# M55M1 register map
File version: 1.0
Registers are 32-bit, read-write, reset 0x0 unless marked. A register's access mark holds for its fields unless they carry their own. Offsets are from the block's base; [hi:lo] are bit positions; {n}, {i} and the like mark numbered series; 'fields as' and 'values as' point back to an identical list.

## SCU — SCU Register Map
Base 0x40402000
0x00 SCU_D0PNS0 — Domain 0 Peripheral Non-secure Attribution Set Register0 (0x4000_0000~0x4001_FFFF)
  [3] NPU — Set NPU to Non-secure State
    0=NPU is a secure module (default); 1=NPU is a non-secure module
0x08 SCU_D0PNS2 — Domain 0 Peripheral Non-secure Attribution Set Register2 (0x4004_0000~0x4005_FFFF)
  [2] SPIM0 — Set SPIM0 to Non-secure State
    0=SPIM0 is a secure module (default); 1=SPIM0 is a non-secure module
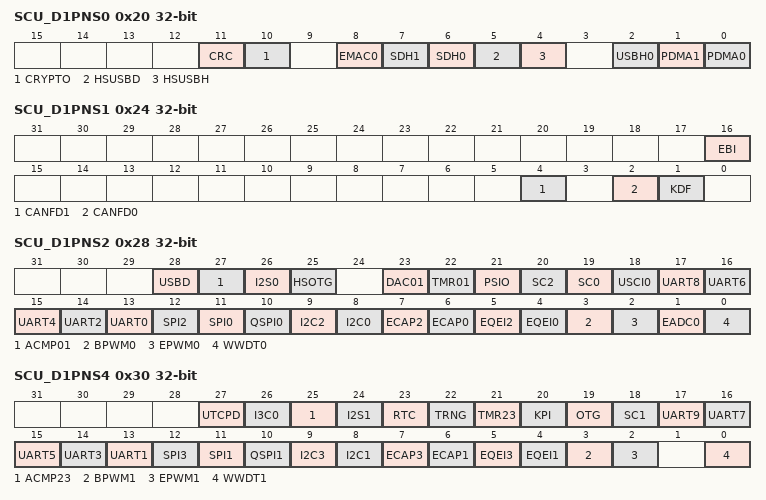
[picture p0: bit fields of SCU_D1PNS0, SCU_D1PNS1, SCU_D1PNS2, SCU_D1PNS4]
0x20 SCU_D1PNS0 — Domain 1 Peripheral Non-secure Attribution Set Register0 (0x4020_0000~0x4021_FFFF)
  [11] CRC — Set CRC to Non-secure State
    0=CRC is a secure module (default); 1=CRC is a non-secure module
  [10] CRYPTO — Set CRYPTO to Non-secure State
    0=CRYPTO is a secure module (default); 1=CRYPTO is a non-secure module
  [8] EMAC0 — Set EMAC0 to Non-secure State
    0=EMAC0 is a secure module (default); 1=EMAC0 is a non-secure module
  [7] SDH1 — Set SDH1 to Non-secure State
    0=SDH1 is a secure module (default); 1=SDH1 is a non-secure module
  [6] SDH0 — Set SDH0 to Non-secure State
    0=SDH0 is a secure module (default); 1=SDH0 is a non-secure module
  [5] HSUSBD — Set HSUSBD to Non-secure State
    0=HSUSBD is a secure module (default); 1=HSUSBD is a non-secure module
  [4] HSUSBH — Set HSUSBH to Non-secure State
    0=HSUSBH is a secure module (default); 1=HSUSBH is a non-secure module
  [2] USBH0 — Set USBH0 to Non-secure State
    0=USBH0 is a secure module (default); 1=USBH0 is a non-secure module
  [1] PDMA1 — Set PDMA1 to Non-secure State
    0=PDMA1 is a secure module (default); 1=PDMA1 is a non-secure module
  [0] PDMA0 — Set PDMA0 to Non-secure State
    0=PDMA0 is a secure module (default); 1=PDMA0 is a non-secure module
0x24 SCU_D1PNS1 — Domain 1 Peripheral Non-secure Attribution Set Register1 (0x4022_0000~0x4023_FFFF)
  [16] EBI — Set EBI to Non-secure State
    0=EBI is a secure module (default); 1=EBI is a non-secure module
  [4] CANFD1 — Set CANFD1 to Non-secure State
    0=CANFD1 is a secure module (default); 1=CANFD1 is a non-secure module
  [2] CANFD0 — Set CANFD0 to Non-secure State
    0=CANFD0 is a secure module (default); 1=CANFD0 is a non-secure module
  [1] KDF — Set KDF to Non-secure State
    0=KDF is a secure module (default); 1=KDF is a non-secure module
0x28 SCU_D1PNS2 — Domain 1 Peripheral Non-secure Attribution Set Register2 (0x4024_0000~0x4025_FFFF)
  [28] USBD — Set USBD to Non-secure State
    0=USBD is a secure module (default); 1=USBD is a non-secure module
  [27] ACMP01 — Set ACMP01 to Non-secure State
    0=ACMP01 is a secure module (default); 1=ACMP01 is a non-secure module
  [26] I2S0 — Set I2S0 to Non-secure State
    0=I2S0 is a secure module (default); 1=I2S0 is a non-secure module
  [25] HSOTG — Set HSOTG to Non-secure State
    0=HSOTG is a secure module (default); 1=HSOTG is a non-secure module
  [23] DAC01 — Set DAC01 to Non-secure State
    0=DAC01 is a secure module (default); 1=DAC01 is a non-secure module
  [22] TMR01 — Set TMR01 to Non-secure State
    0=TMR01 is a secure module (default); 1=TMR01 is a non-secure module
  [21] PSIO — Set PSIO to Non-secure State
    0=PSIO is a secure module (default); 1=PSIO is a non-secure module
  [20] SC2 — Set SC2 to Non-secure State
    0=SC2 is a secure module (default); 1=SC2 is a non-secure module
  [19] SC0 — Set SC0 to Non-secure State
    0=SC0 is a secure module (default); 1=SC0 is a non-secure module
  [18] USCI0 — Set USCI0 to Non-secure State
    0=USCI0 is a secure module (default); 1=USCI0 is a non-secure module
  [17] UART8 — Set UART8 to Non-secure State
    0=UART8 is a secure module (default); 1=UART8 is a non-secure module
  [16] UART6 — Set UART6 to Non-secure State
    0=UART6 is a secure module (default); 1=UART6 is a non-secure module
  [15] UART4 — Set UART4 to Non-secure State
    0=UART4 is a secure module (default); 1=UART4 is a non-secure module
  [14] UART2 — Set UART2 to Non-secure State
    0=UART2 is a secure module (default); 1=UART2 is a non-secure module
  [13] UART0 — Set UART0 to Non-secure State
    0=UART0 is a secure module (default); 1=UART0 is a non-secure module
  [12] SPI2 — Set SPI2 to Non-secure State
    0=SPI2 is a secure module (default); 1=SPI2 is a non-secure module
  [11] SPI0 — Set SPI0 to Non-secure State
    0=SPI0 is a secure module (default); 1=SPI0 is a non-secure module
  [10] QSPI0 — Set QSPI0 to Non-secure State
    0=QSPI0 is a secure module (default); 1=QSPI0 is a non-secure module
  [9] I2C2 — Set I2C2 to Non-secure State
    0=I2C2 is a secure module (default); 1=I2C2 is a non-secure module
  [8] I2C0 — Set I2C0 to Non-secure State
    0=I2C0 is a secure module (default); 1=I2C0 is a non-secure module
  [7] ECAP2 — Set ECAP2 to Non-secure State
    0=ECAP2 is a secure module (default); 1=ECAP2 is a non-secure module
  [6] ECAP0 — Set ECAP0 to Non-secure State
    0=ECAP0 is a secure module (default); 1=ECAP0 is a non-secure module
  [5] EQEI2 — Set EQEI2 to Non-secure State
    0=EQEI2 is a secure module (default); 1=EQEI2 is a non-secure module
  [4] EQEI0 — Set EQEI0 to Non-secure State
    0=EQEI0 is a secure module (default); 1=EQEI0 is a non-secure module
  [3] BPWM0 — Set BPWM0 to Non-secure State
    0=BPWM0 is a secure module (default); 1=BPWM0 is a non-secure module
  [2] EPWM0 — Set EPWM0 to Non-secure State
    0=EPWM0 is a secure module (default); 1=EPWM0 is a non-secure module
  [1] EADC0 — Set EADC0 to Non-secure State
    0=EADC0 is a secure module (default); 1=EADC0 is a non-secure module
  [0] WWDT0 — Set WWDT0 to Non-secure State
    0=WWDT0 is a secure module (default); 1=WWDT0 is a non-secure module
0x30 SCU_D1PNS4 — Domain 1 Peripheral Non-secure Attribution Set Register4 (0x4028_0000~0x4029_FFFF)
  [27] UTCPD — Set UTCPD to Non-secure State
    0=UTCPD is a secure module (default); 1=UTCPD is a non-secure module
  [26] I3C0 — Set I3C0 to Non-secure State
    0=I3C0 is a secure module (default); 1=I3C0 is a non-secure module
  [25] ACMP23 — Set ACMP23 to Non-secure State
    0=ACMP23 is a secure module (default); 1=ACMP23 is a non-secure module
  [24] I2S1 — Set I2S1 to Non-secure State
    0=I2S1 is a secure module (default); 1=I2S1 is a non-secure module
  [23] RTC — Set RTC to Non-secure State
    0=RTC is a secure module (default); 1=RTC is a non-secure module
  [22] TRNG — Set TRNG to Non-secure State
    0=TRNG is a secure module (default); 1=TRNG is a non-secure module
  [21] TMR23 — Set TMR23 to Non-secure State
    0=TMR23 is a secure module (default); 1=TMR23 is a non-secure module
  [20] KPI — Set KPI to Non-secure State
    0=KPI is a secure module (default); 1=KPI is a non-secure module
  [19] OTG — Set OTG to Non-secure State
    0=OTG is a secure module (default); 1=OTG is a non-secure module
  [18] SC1 — Set SC1 to Non-secure State
    0=SC1 is a secure module (default); 1=SC1 is a non-secure module
  [17] UART9 — Set UART9 to Non-secure State
    0=UART9 is a secure module (default); 1=UART9 is a non-secure module
  [16] UART7 — Set UART7 to Non-secure State
    0=UART7 is a secure module (default); 1=UART7 is a non-secure module
  [15] UART5 — Set UART5 to Non-secure State
    0=UART5 is a secure module (default); 1=UART5 is a non-secure module
  [14] UART3 — Set UART3 to Non-secure State
    0=UART3 is a secure module (default); 1=UART3 is a non-secure module
  [13] UART1 — Set UART1 to Non-secure State
    0=UART1 is a secure module (default); 1=UART1 is a non-secure module
  [12] SPI3 — Set SPI3 to Non-secure State
    0=SPI3 is a secure module (default); 1=SPI3 is a non-secure module
  [11] SPI1 — Set SPI1 to Non-secure State
    0=SPI1 is a secure module (default); 1=SPI1 is a non-secure module
  [10] QSPI1 — Set QSPI1 to Non-secure State
    0=QSPI1 is a secure module (default); 1=QSPI1 is a non-secure module
  [9] I2C3 — Set I2C3 to Non-secure State
    0=I2C3 is a secure module (default); 1=I2C3 is a non-secure module
  [8] I2C1 — Set I2C1 to Non-secure State
    0=I2C1 is a secure module (default); 1=I2C1 is a non-secure module
  [7] ECAP3 — Set ECAP3 to Non-secure State
    0=ECAP3 is a secure module (default); 1=ECAP3 is a non-secure module
  [6] ECAP1 — Set ECAP1 to Non-secure State
    0=ECAP1 is a secure module (default); 1=ECAP1 is a non-secure module
  [5] EQEI3 — Set EQEI3 to Non-secure State
    0=EQEI3 is a secure module (default); 1=EQEI3 is a non-secure module
  [4] EQEI1 — Set EQEI1 to Non-secure State
    0=EQEI1 is a secure module (default); 1=EQEI1 is a non-secure module
  [3] BPWM1 — Set BPWM1 to Non-secure State
    0=BPWM1 is a secure module (default); 1=BPWM1 is a non-secure module
  [2] EPWM1 — Set EPWM1 to Non-secure State
    0=EPWM1 is a secure module (default); 1=EPWM1 is a non-secure module
  [0] WWDT1 — Set WWDT1 to Non-secure State
    0=WWDT1 is a secure module (default); 1=WWDT1 is a non-secure module
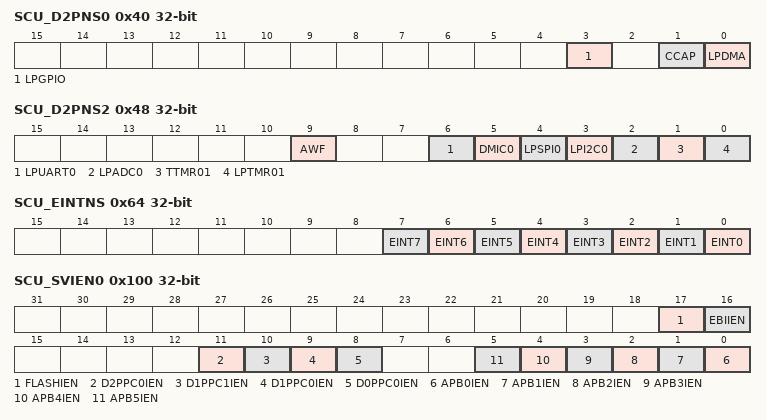
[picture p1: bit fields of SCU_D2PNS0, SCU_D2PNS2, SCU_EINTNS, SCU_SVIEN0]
0x40 SCU_D2PNS0 — Domain 2 Peripheral Non-secure Attribution Set Register0 (0x4040_0000~0x4041_FFFF)
  [3] LPGPIO — Set LPGPIO to Non-secure State
    0=LPGPIO is a secure module (default); 1=LPGPIO is a non-secure module
  [1] CCAP — Set CCAP to Non-secure State
    0=CCAP is a secure module (default); 1=CCAP is a non-secure module
  [0] LPDMA — Set LPDMA to Non-secure State
    0=LPDMA is a secure module (default); 1=LPDMA is a non-secure module
0x48 SCU_D2PNS2 — Domain 2 Peripheral Non-secure Attribution Set Register2 (0x4044_0000~0x4045_FFFF)
  [9] AWF — Set AWF to Non-secure State
    0=AWF is a secure module (default); 1=AWF is a non-secure module
  [6] LPUART0 — Set LPUART0 to Non-secure State
    0=LPUART0 is a secure module (default); 1=LPUART0 is a non-secure module
  [5] DMIC0 — Set DMIC0 to Non-secure State
    0=DMIC0 is a secure module (default); 1=DMIC0 is a non-secure module
  [4] LPSPI0 — Set LPSPI0 to Non-secure State
    0=LPSPI0 is a secure module (default); 1=LPSPI0 is a non-secure module
  [3] LPI2C0 — Set LPI2C0 to Non-secure State
    0=LPI2C0 is a secure module (default); 1=LPI2C0 is a non-secure module
  [2] LPADC0 — Set LPADC0 to Non-secure State
    0=LPADC0 is a secure module (default); 1=LPADC0 is a non-secure module
  [1] TTMR01 — Set TTMR01 to Non-secure State
    0=TTMR01 is a secure module (default); 1=TTMR01 is a non-secure module
  [0] LPTMR01 — Set LPTMR01 to Non-secure State
    0=LPTMR01 is a secure module (default); 1=LPTMR01 is a non-secure module
0x60 SCU_FNSADDR ro reset not defined — Flash Non-secure Boundary Address Register
  [31:0] FNSADDR — Flash Non-secure Boundary Address. Indicate the base address of Non-secure region set in user configuration. Refer to FMC section for more details.
0x64 SCU_EINTNS — EINT Non-secure Attribution Set Register
  [n] EINT{n} (n=0..7) — Set EINT{n} to Non-secure State
    0=EINT{n} is a secure module (default); 1=EINT{n} is a non-secure module
0x70 SCU_IONS0 — I/O Non-secure Attribution Set Register0
  [15:0] PA — Set GPIO Port A to Non-secure State. Write 1 to set PA to non-secure state. Each bit configures one pin in GPIO port A.
    0=GPIO port A is secure (default); 1=GPIO port A is non-secure
0x74 SCU_IONS1 — I/O Non-secure Attribution Set Register1
  [15:0] PB — Set GPIO Port B to Non-secure State. Write 1 to set PB to non-secure state. Each bit configures one pin in GPIO port B.
    0=GPIO port B is secure (default); 1=GPIO port B is non-secure
0x78 SCU_IONS2 — I/O Non-secure Attribution Set Register2
  [15:0] PC — Set GPIO Port C to Non-secure State. Write 1 to set PC to non-secure state. Each bit configures one pin in GPIO port C.
    0=GPIO port C is secure (default); 1=GPIO port C is non-secure
0x7C SCU_IONS3 — I/O Non-secure Attribution Set Register3
  [15:0] PD — Set GPIO Port D to Non-secure State. Write 1 to set PD to non-secure state. Each bit configures one pin in GPIO port D.
    0=GPIO port D is secure (default); 1=GPIO port D is non-secure
0x80 SCU_IONS4 — I/O Non-secure Attribution Set Register4
  [15:0] PE — Set GPIO Port E to Non-secure State. Write 1 to set PE to non-secure state. Each bit configures one pin in GPIO port E.
    0=GPIO port E is secure (default); 1=GPIO port E is non-secure
0x84 SCU_IONS5 — I/O Non-secure Attribution Set Register5
  [15:0] PF — Set GPIO Port F to Non-secure State. Write 1 to set PF to non-secure state. Each bit configures one pin in GPIO port F.
    0=GPIO port F is secure (default); 1=GPIO port F is non-secure
0x88 SCU_IONS6 — I/O Non-secure Attribution Set Register6
  [15:0] PG — Set GPIO Port G to Non-secure State. Write 1 to set PG to non-secure state. Each bit configures one pin in GPIO port G.
    0=GPIO port G is secure (default); 1=GPIO port G is non-secure
0x8C SCU_IONS7 — I/O Non-secure Attribution Set Register7
  [15:0] PH — Set GPIO Port H to Non-secure State. Write 1 to set PH to non-secure state. Each bit configures one pin in GPIO port H.
    0=GPIO port H is secure (default); 1=GPIO port H is non-secure
0x90 SCU_IONS8 — I/O Non-secure Attribution Set Register8
  [15:0] PI — Set GPIO Port I to Non-secure State. Write 1 to set PI to non-secure state. Each bit configures one pin in GPIO port I.
    0=GPIO port I is secure (default); 1=GPIO port I is non-secure
0x94 SCU_IONS9 — I/O Non-secure Attribution Set Register9
  [15:0] PJ — Set GPIO Port J to Non-secure State. Write 1 to set PJ to non-secure state. Each bit configures one pin in GPIO port J.
    0=GPIO port J is secure (default); 1=GPIO port J is non-secure
0x100 SCU_SVIEN0 — Security Violation Interrupt Enable Register - Slave peripherals
  [17] FLASHIEN — FLASH Security Violation Interrupt Enable Bit
    0=Interrupt triggered from security violation of FLASH Disabled; 1=Interrupt triggered from security violation of FLASH Enabled
  [16] EBIIEN — EBI Security Violation Interrupt Enable Bit
    0=Interrupt triggered from security violation of EBI Disabled; 1=Interrupt triggered from security violation of EBI Enabled
  [11] D2PPC0IEN — D2PPC0 Security Violation Interrupt Enable Bit
    0=Interrupt triggered from security violation of D2PPC0 Disabled; 1=Interrupt triggered from security violation of D2PPC0 Enabled
  [10] D1PPC1IEN — D1PPC1 Security Violation Interrupt Enable Bit
    0=Interrupt triggered from security violation of D1PPC1 Disabled; 1=Interrupt triggered from security violation of D1PPC1 Enabled
  [9] D1PPC0IEN — D1PPC0 Security Violation Interrupt Enable Bit
    0=Interrupt triggered from security violation of D1PPC0 Disabled; 1=Interrupt triggered from security violation of D1PPC0 Enabled
  [8] D0PPC0IEN — D0PPC0 Security Violation Interrupt Enable Bit
    0=Interrupt triggered from security violation of D0PPC0 Disabled; 1=Interrupt triggered from security violation of D0PPC0 Enabled
  [n] APB{n}IEN (n=0..5) — APB{n} Security Violation Interrupt Enable Bit
    0=Interrupt triggered from security violation of APB{n} Disabled; 1=Interrupt triggered from security violation of APB{n} Enabled
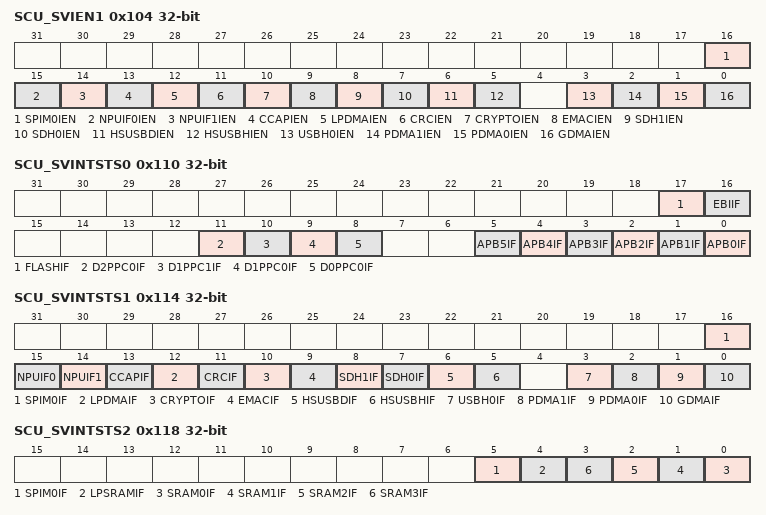
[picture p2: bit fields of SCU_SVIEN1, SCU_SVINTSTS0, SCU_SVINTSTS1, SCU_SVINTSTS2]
0x104 SCU_SVIEN1 — Security Violation Interrupt Enable Register - Master peripherals (MSC)
  [16] SPIM0IEN — SPIM0 Security Violation Interrupt Enable Bit
    0=Interrupt triggered from security violation of SPIM0 Disabled.1 = Interrupt triggered from security violation of SPIM0 Enabled
  [15] NPUIF0IEN — NPU Interface 0 Security Violation Interrupt Enable Bit
    0=Interrupt triggered from security violation of NPU Interface 0 Disabled.1 = Interrupt triggered from security violation of NPU Interface 0 Enabled
  [14] NPUIF1IEN — NPU Interface 1 Security Violation Interrupt Enable Bit
    0=Interrupt triggered from security violation of NPU Interface 1 Disabled.1 = Interrupt triggered from security violation of NPU Interface 1 Enabled
  [13] CCAPIEN — CCAP Security Violation Interrupt Enable Bit
    0=Interrupt triggered from security violation of CCAP Disabled.1 = Interrupt triggered from security violation of CCAP Enabled
  [12] LPDMAIEN — LPDMA Security Violation Interrupt Enable Bit
    0=Interrupt triggered from security violation of LPDMA Disabled.1 = Interrupt triggered from security violation of LPDMA Enabled
  [11] CRCIEN — CRC Security Violation Interrupt Enable Bit
    0=Interrupt triggered from security violation of CRC Disabled.1 = Interrupt triggered from security violation of CRC Enabled
  [10] CRYPTOIEN — CRYPTO Security Violation Interrupt Enable Bit
    0=Interrupt triggered from security violation of CRYPTO Disabled.1 = Interrupt triggered from security violation of CRYPTO Enabled
  [9] EMACIEN — EMAC Security Violation Interrupt Enable Bit
    0=Interrupt triggered from security violation of EMAC Disabled.1 = Interrupt triggered from security violation of EMAC Enabled
  [8] SDH1IEN — SDH1 Security Violation Interrupt Enable Bit
    0=Interrupt triggered from security violation of SDH1 Disabled.1 = Interrupt triggered from security violation of SDH1 Enabled
  [7] SDH0IEN — SDH0 Security Violation Interrupt Enable Bit
    0=Interrupt triggered from security violation of SDH0 Disabled.1 = Interrupt triggered from security violation of SDH0 Enabled
  [6] HSUSBDIEN — HSUSBD Security Violation Interrupt Enable Bit
    0=Interrupt triggered from security violation of HSUSBD Disabled.1 = Interrupt triggered from security violation of HSUSBD Enabled
  [5] HSUSBHIEN — HSUSBH Security Violation Interrupt Enable Bit
    0=Interrupt triggered from security violation of HSUSBH Disabled.1 = Interrupt triggered from security violation of HSUSBH Enabled
  [3] USBH0IEN — USBH0 Security Violation Interrupt Enable Bit
    0=Interrupt triggered from security violation of USBH0 Disabled.1 = Interrupt triggered from security violation of USBH0 Enabled
  [2] PDMA1IEN — PDMA1 Security Violation Interrupt Enable Bit
    0=Interrupt triggered from security violation of PDMA1 Disabled.1 = Interrupt triggered from security violation of PDMA1 Enabled
  [1] PDMA0IEN — PDMA0 Security Violation Interrupt Enable Bit
    0=Interrupt triggered from security violation of PDMA Disabled.1 = Interrupt triggered from security violation of PDMA Enabled
  [0] GDMAIEN — GDMA Security Violation Interrupt Enable Bit
    0=Interrupt triggered from security violation of GDMA Disabled.1 = Interrupt triggered from security violation of GDMA Enabled
0x110 SCU_SVINTSTS0 — Security Violation Interrupt Status Register - Slave peripherals
  [17] FLASHIF — FLASH Security Violation Interrupt Status. Note: Write 1 to clear the interrupt flag.
    0=No FLASH violation interrupt event; 1=There is at least a FLASH violation interrupt event
  [16] EBIIF — EBI Security Violation Interrupt Status. Note: Write 1 to clear the interrupt flag.
    0=No EBI violation interrupt event; 1=There is at least a EBI violation interrupt event
  [11] D2PPC0IF — D2PPC0 Security Violation Interrupt Status. Note: Write 1 to clear the interrupt flag.
    0=No D2PPC0 violation interrupt event; 1=There is at least a D2PPC0 violation interrupt event
  [10] D1PPC1IF — D1PPC1 Security Violation Interrupt Status. Note: Write 1 to clear the interrupt flag.
    0=No D1PPC1 violation interrupt event; 1=There is at least a D1PPC1 violation interrupt event
  [9] D1PPC0IF — D1PPC0 Security Violation Interrupt Status. Note: Write 1 to clear the interrupt flag.
    0=No D1PPC0 violation interrupt event; 1=There is at least a D1PPC0 violation interrupt event
  [8] D0PPC0IF — D0PPC0 Security Violation Interrupt Status. Note: Write 1 to clear the interrupt flag.
    0=No D0PPC0 violation interrupt event; 1=There is at least a D0PPC0 violation interrupt event
  [n] APB{n}IF (n=0..5) — APB{n} Security Violation Interrupt Status. Note: Write 1 to clear the interrupt flag.
    0=No APB{n} violation interrupt event; 1=There is at least a APB{n} violation interrupt event
0x114 SCU_SVINTSTS1 — Security Violation Interrupt Status Register - Master peripherals (MSC)
  [16] SPIM0IF — SPIM0 Security Violation Interrupt Status. Note: Write 1 to clear the interrupt flag.
    0=No SPIM0 violation interrupt event; 1=There is at least a SPIM0 violation interrupt event
  [15] NPUIF0 — NPU Interface 0 Security Violation Interrupt Status. Note: Write 1 to clear the interrupt flag.
    0=No NPU Interface 0 violation interrupt event; 1=There is at least a NPU Interface 0 violation interrupt event
  [14] NPUIF1 — NPU Interface 1 Security Violation Interrupt Status. Note: Write 1 to clear the interrupt flag.
    0=No NPU Interface 1 violation interrupt event; 1=There is at least a NPU Interface 1 violation interrupt event
  [13] CCAPIF — CCAP Security Violation Interrupt Status. Note: Write 1 to clear the interrupt flag.
    0=No CCAP violation interrupt event; 1=There is at least a CCAP violation interrupt event
  [12] LPDMAIF — LPDMA Security Violation Interrupt Status. Note: Write 1 to clear the interrupt flag.
    0=No LPDMA violation interrupt event; 1=There is at least a LPDMA violation interrupt event
  [11] CRCIF — CRC Security Violation Interrupt Status. Note: Write 1 to clear the interrupt flag.
    0=No CRC violation interrupt event; 1=There is at least a CRC violation interrupt event
  [10] CRYPTOIF — CRYPTO Security Violation Interrupt Status. Note: Write 1 to clear the interrupt flag.
    0=No CRYPTO violation interrupt event; 1=There is at least a CRYPTO violation interrupt event
  [9] EMACIF — EMAC Security Violation Interrupt Status. Note: Write 1 to clear the interrupt flag.
    0=No EMAC violation interrupt event; 1=There is at least a EMAC violation interrupt event
  [8] SDH1IF — SDH1 Security Violation Interrupt Status. Note: Write 1 to clear the interrupt flag.
    0=No SDH1 violation interrupt event; 1=There is at least a SDH1 violation interrupt event
  [7] SDH0IF — SDH0 Security Violation Interrupt Status. Note: Write 1 to clear the interrupt flag.
    0=No SDH0 violation interrupt event; 1=There is at least a SDH0 violation interrupt event
  [6] HSUSBDIF — HSUSBD Security Violation Interrupt Status. Note: Write 1 to clear the interrupt flag.
    0=No HSUSBD violation interrupt event; 1=There is at least a HSUSBD violation interrupt event
  [5] HSUSBHIF — HSUSBH Security Violation Interrupt Status. Note: Write 1 to clear the interrupt flag.
    0=No HSUSBH violation interrupt event; 1=There is at least a HSUSBH violation interrupt event
  [3] USBH0IF — USBH0 Security Violation Interrupt Status. Note: Write 1 to clear the interrupt flag.
    0=No USBH0 violation interrupt event; 1=There is at least a USBH0 violation interrupt event
  [2] PDMA1IF — PDMA1 Security Violation Interrupt Status. Note: Write 1 to clear the interrupt flag.
    0=No PDMA1 violation interrupt event; 1=There is at least a PDMA1 violation interrupt event
  [1] PDMA0IF — PDMA0 Security Violation Interrupt Status. Note: Write 1 to clear the interrupt flag.
    0=No PDMA0 violation interrupt event; 1=There is at least a PDMA0 violation interrupt event
  [0] GDMAIF — GDMA Security Violation Interrupt Status. Note: Write 1 to clear the interrupt flag.
    0=No GDMA violation interrupt event; 1=There is at least a GDMA violation interrupt event
0x118 SCU_SVINTSTS2 ro — Security Violation Interrupt Status Register - Memory peripherals (MPC)
  [5] SPIM0IF — SPIM0 Security Violation Interrupt Status
    values as SCU_SVINTSTS1.SPIM0IF
  [4] LPSRAMIF — LPSRAM Security Violation Interrupt Status
    0=No LPSRAM violation interrupt event; 1=There is at least a LPSRAM violation interrupt event
  [n] SRAM{n}IF (n=0..3) — SRAM{n} Security Violation Interrupt Status
    0=No SRAM{n} violation interrupt event; 1=There is at least a SRAM{n} violation interrupt event
{0x120+4i} SCU_APB{i}PVSRC ro (reset mask 0xFFFFFF00) (i=0..5) — APB{i} Security Policy Violation Source
  [4:0] MASTER — Master Violating Security Policy. Indicate which master invokes the security violation. Others are undefined.
    0=Core processor; 1=PDMA0; 2=PDMA1; 3=USBH0; 5=HSUSBH; 6=HSUSBD; 7=SDH0; 8=SDH1; 9=EMAC; 10=CRYPTO; 11=CRC; 12=GDMA; 13=NPU; 14=LPDMA; 15=CCAP; 16=SPIM0
0x140 SCU_D0PPC0PVSRC ro (reset mask 0xFFFFFF00) — D0PPC0 Security Policy Violation Source
  fields as SCU_APB0PVSRC
0x144 SCU_D1PPC0PVSRC ro (reset mask 0xFFFFFF00) — D1PPC0 Security Policy Violation Source
  fields as SCU_APB0PVSRC
0x148 SCU_D1PPC1PVSRC ro (reset mask 0xFFFFFF00) — D1PPC1 Security Policy Violation Source
  fields as SCU_APB0PVSRC
0x14C SCU_D2PPC0PVSRC ro (reset mask 0xFFFFFF00) — D2PPC0 Security Policy Violation Source
  fields as SCU_APB0PVSRC
0x160 SCU_EBIPVSRC ro (reset mask 0xFFFFFF00) — EBI Security Policy Violation Source
  fields as SCU_APB0PVSRC
0x164 SCU_FLASHPVSRC ro (reset mask 0xFFFFFF00) — FLASH Security Policy Violation Source
  fields as SCU_APB0PVSRC
{0x1A0+4i} SCU_APB{i}PVA ro reset not defined (i=0..5) — APB{i} Violation Address
  [31:0] VIOADDR — Violation Address. Indicate the target address of the access, which invokes the security violation.
0x1C0 SCU_D0PPC0PVA ro reset not defined — D0PPC0 Violation Address
  fields as SCU_APB0PVA
0x1C4 SCU_D1PPC0PVA ro reset not defined — D1PPC0 Violation Address
  fields as SCU_APB0PVA
0x1C8 SCU_D1PPC1PVA ro reset not defined — D1PPC1 Violation Address
  fields as SCU_APB0PVA
0x1CC SCU_D2PPC0PVA ro reset not defined — D2PPC0 Violation Address
  fields as SCU_APB0PVA
0x1E0 SCU_EBIPVA ro reset not defined — EBI Violation Address
  fields as SCU_APB0PVA
0x1E4 SCU_FLASHPVA ro reset not defined — FLASH Violation Address
  fields as SCU_APB0PVA
0x220 SCU_GDMAMVA ro reset not defined — GDMA Violation Address
  fields as SCU_APB0PVA
0x224 SCU_PDMA0MVA ro reset not defined — PDMA Violation Address
  fields as SCU_APB0PVA
0x228 SCU_PDMA1MVA ro reset not defined — PDMA1 Violation Address
  fields as SCU_APB0PVA
0x22C SCU_USBH0MVA ro reset not defined — USBH0 Violation Address
  fields as SCU_APB0PVA
0x234 SCU_HSUSBHMVA ro reset not defined — HSUSBH Violation Address
  fields as SCU_APB0PVA
0x238 SCU_HSUSBDMVA ro reset not defined — HSUSBD Violation Address
  fields as SCU_APB0PVA
0x23C SCU_SDH0MVA ro reset not defined — SDH Violation Address
  fields as SCU_APB0PVA
0x240 SCU_SDH1MVA ro reset not defined — SDH1 Violation Address
  fields as SCU_APB0PVA
0x244 SCU_EMACMVA ro reset not defined — EMAC Violation Address
  fields as SCU_APB0PVA
0x248 SCU_CRYPTOMVA ro reset not defined — CRYPTO Violation Address
  fields as SCU_APB0PVA
0x24C SCU_CRCMVA ro reset not defined — CRC Violation Address
  fields as SCU_APB0PVA
0x250 SCU_LPDMAMVA ro reset not defined — LPDMA Violation Address
  fields as SCU_APB0PVA
0x254 SCU_CCAPMVA ro reset not defined — CCAP Violation Address
  fields as SCU_APB0PVA
0x258 SCU_NPUIF1MVA ro reset not defined — NPU Interface 1 Violation Address
  fields as SCU_APB0PVA
0x25C SCU_NPUIF0MVA ro reset not defined — NPU Interface 0 Violation Address
  fields as SCU_APB0PVA
0x260 SCU_SPIM0MVA ro reset not defined — SPIM 0 Master Violation Address
  fields as SCU_APB0PVA
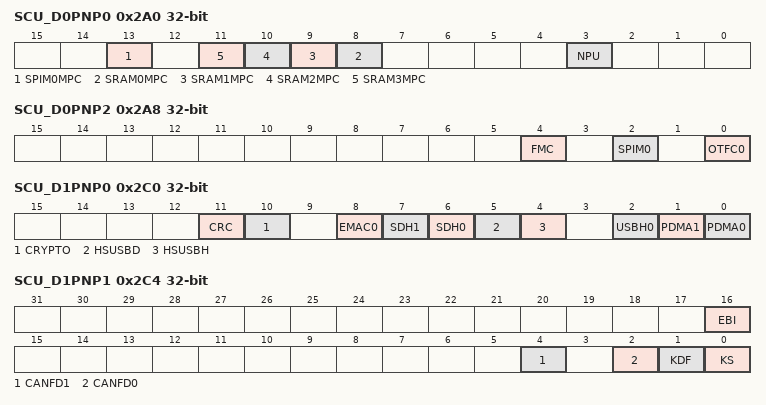
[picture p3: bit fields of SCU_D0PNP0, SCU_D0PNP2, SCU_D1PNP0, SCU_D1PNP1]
0x2A0 SCU_D0PNP0 — Domain 0 Peripheral Privilege Attribution Set Register0 (0x4000_0000~0x4001_FFFF)
  [13] SPIM0MPC — Set SPIM0MPC to Non-privileged State
    0=SPIM0MPC is a privileged module (default); 1=SPIM0MPC is a non-privileged module
  [n+8] SRAM{n}MPC (n=0..3) — Set SRAM{n}MPC to Non-privileged State
    0=SRAM{n}MPC is a privileged module (default); 1=SRAM{n}MPC is a non-privileged module
  [3] NPU — Set NPU to Non-privileged State
    0=NPU is a privileged module (default); 1=NPU is a non-privileged module
0x2A8 SCU_D0PNP2 — Domain 0 Peripheral Privilege Attribution Set Register2 (0x4004_0000~0x4005_FFFF)
  [4] FMC — Set FMC to Non-privileged State
    0=FMC is a privileged module (default); 1=FMC is a non-privileged module
  [2] SPIM0 — Set SPIM0 to Non-privileged State
    0=SPIM0 is a privileged module (default); 1=SPIM0 is a non-privileged module
  [0] OTFC0 — Set OTFC0 to Non-privileged State
    0=OTFC0 is a privileged module (default); 1=OTFC0 is a non-privileged module
0x2C0 SCU_D1PNP0 — Domain 1 Peripheral Privilege Attribution Set Register0 (0x4020_0000~0x4021_FFFF)
  [11] CRC — Set CRC to Non-privileged State
    0=CRC is a privileged module (default); 1=CRC is a non-privileged module
  [10] CRYPTO — Set CRYPTO to Non-privileged State
    0=CRYPTO is a privileged module (default); 1=CRYPTO is a non-privileged module
  [8] EMAC0 — Set EMAC0 to Non-privileged State
    0=EMAC0 is a privileged module (default); 1=EMAC0 is a non-privileged module
  [7] SDH1 — Set SDH1 to Non-privileged State
    0=SDH1 is a privileged module (default); 1=SDH1 is a non-privileged module
  [6] SDH0 — Set SDH0 to Non-privileged State
    0=SDH0 is a privileged module (default); 1=SDH0 is a non-privileged module
  [5] HSUSBD — Set HSUSBD to Non-privileged State
    0=HSUSBD is a privileged module (default); 1=HSUSBD is a non-privileged module
  [4] HSUSBH — Set HSUSBH to Non-privileged State
    0=HSUSBH is a privileged module (default); 1=HSUSBH is a non-privileged module
  [2] USBH0 — Set USBH0 to Non-privileged State
    0=USBH0 is a privileged module (default); 1=USBH0 is a non-privileged module
  [1] PDMA1 — Set PDMA1 to Non-privileged State
    0=PDMA1 is a privileged module (default); 1=PDMA1 is a non-privileged module
  [0] PDMA0 — Set PDMA0 to Non-privileged State
    0=PDMA0 is a privileged module (default); 1=PDMA0 is a non-privileged module
0x2C4 SCU_D1PNP1 — Domain 1 Peripheral Privilege Attribution Set Register1 (0x4022_0000~0x4023_FFFF)
  [16] EBI — Set EBI to Non-privileged State
    0=EBI is a privileged module (default); 1=EBI is a non-privileged module
  [4] CANFD1 — Set CANFD1 to Non-privileged State
    0=CANFD1 is a privileged module (default); 1=CANFD1 is a non-privileged module
  [2] CANFD0 — Set CANFD0 to Non-privileged State
    0=CANFD0 is a privileged module (default); 1=CANFD0 is a non-privileged module
  [1] KDF — Set KDF to Non-privileged State
    0=KDF is a privileged module (default); 1=KDF is a non-privileged module
  [0] KS — Set KS to Non-privileged State
    0=KS is a privileged module (default); 1=KS is a non-privileged module
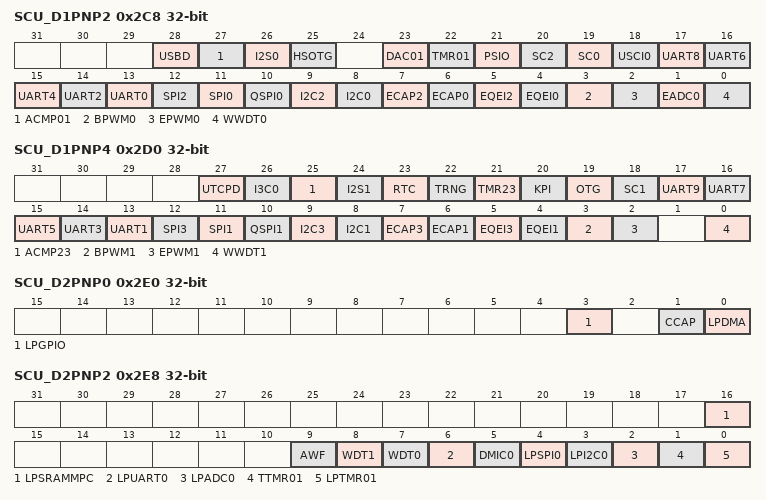
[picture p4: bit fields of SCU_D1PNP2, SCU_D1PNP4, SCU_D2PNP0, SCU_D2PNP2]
0x2C8 SCU_D1PNP2 — Domain 1 Peripheral Privilege Attribution Set Register2 (0x4024_0000~0x4025_FFFF)
  [28] USBD — Set USBD to Non-privileged State
    0=USBD is a privileged module (default); 1=USBD is a non-privileged module
  [27] ACMP01 — Set ACMP01 to Non-privileged State
    0=ACMP01 is a privileged module (default); 1=ACMP01 is a non-privileged module
  [26] I2S0 — Set I2S0 to Non-privileged State
    0=I2S0 is a privileged module (default); 1=I2S0 is a non-privileged module
  [25] HSOTG — Set HSOTG to Non-privileged State
    0=HSOTG is a privileged module (default); 1=HSOTG is a non-privileged module
  [23] DAC01 — Set DAC01 to Non-privileged State
    0=DAC01 is a privileged module (default); 1=DAC01 is a non-privileged module
  [22] TMR01 — Set TMR01 to Non-privileged State
    0=TMR01 is a privileged module (default); 1=TMR01 is a non-privileged module
  [21] PSIO — Set PSIO to Non-privileged State
    0=PSIO is a privileged module (default); 1=PSIO is a non-privileged module
  [20] SC2 — Set SC2 to Non-privileged State
    0=SC2 is a privileged module (default); 1=SC2 is a non-privileged module
  [19] SC0 — Set SC0 to Non-privileged State
    0=SC0 is a privileged module (default); 1=SC0 is a non-privileged module
  [18] USCI0 — Set USCI0 to Non-privileged State
    0=USCI0 is a privileged module (default); 1=USCI0 is a non-privileged module
  [17] UART8 — Set UART8 to Non-privileged State
    0=UART8 is a privileged module (default); 1=UART8 is a non-privileged module
  [16] UART6 — Set UART6 to Non-privileged State
    0=UART6 is a privileged module (default); 1=UART6 is a non-privileged module
  [15] UART4 — Set UART4 to Non-privileged State
    0=UART4 is a privileged module (default); 1=UART4 is a non-privileged module
  [14] UART2 — Set UART2 to Non-privileged State
    0=UART2 is a privileged module (default); 1=UART2 is a non-privileged module
  [13] UART0 — Set UART0 to Non-privileged State
    0=UART0 is a privileged module (default); 1=UART0 is a non-privileged module
  [12] SPI2 — Set SPI2 to Non-privileged State
    0=SPI2 is a privileged module (default); 1=SPI2 is a non-privileged module
  [11] SPI0 — Set SPI0 to Non-privileged State
    0=SPI0 is a privileged module (default); 1=SPI0 is a non-privileged module
  [10] QSPI0 — Set QSPI0 to Non-privileged State
    0=QSPI0 is a privileged module (default); 1=QSPI0 is a non-privileged module
  [9] I2C2 — Set I2C2 to Non-privileged State
    0=I2C2 is a privileged module (default); 1=I2C2 is a non-privileged module
  [8] I2C0 — Set I2C0 to Non-privileged State
    0=I2C0 is a privileged module (default); 1=I2C0 is a non-privileged module
  [7] ECAP2 — Set ECAP2 to Non-privileged State
    0=ECAP2 is a privileged module (default); 1=ECAP2 is a non-privileged module
  [6] ECAP0 — Set ECAP0 to Non-privileged State
    0=ECAP0 is a privileged module (default); 1=ECAP0 is a non-privileged module
  [5] EQEI2 — Set EQEI2 to Non-privileged State
    0=EQEI2 is a privileged module (default); 1=EQEI2 is a non-privileged module
  [4] EQEI0 — Set EQEI0 to Non-privileged State
    0=EQEI0 is a privileged module (default); 1=EQEI0 is a non-privileged module
  [3] BPWM0 — Set BPWM0 to Non-privileged State
    0=BPWM0 is a privileged module (default); 1=BPWM0 is a non-privileged module
  [2] EPWM0 — Set EPWM0 to Non-privileged State
    0=EPWM0 is a privileged module (default); 1=EPWM0 is a non-privileged module
  [1] EADC0 — Set EADC0 to Non-privileged State
    0=EADC0 is a privileged module (default); 1=EADC0 is a non-privileged module
  [0] WWDT0 — Set WWDT0 to Non-privileged State
    0=WWDT0 is a privileged module (default); 1=WWDT0 is a non-privileged module
0x2D0 SCU_D1PNP4 — Domain 1 Peripheral Privilege Attribution Set Register4 (0x4028_0000~0x4029_FFFF)
  [27] UTCPD — Set UTCPD to Non-privileged State
    0=UTCPD is a privileged module (default); 1=UTCPD is a non-privileged module
  [26] I3C0 — Set I3C0 to Non-privileged State
    0=I3C0 is a privileged module (default); 1=I3C0 is a non-privileged module
  [25] ACMP23 — Set ACMP23 to Non-privileged State
    0=ACMP23 is a privileged module (default); 1=ACMP23 is a non-privileged module
  [24] I2S1 — Set I2S1 to Non-privileged State
    0=I2S1 is a privileged module (default); 1=I2S1 is a non-privileged module
  [23] RTC — Set RTC to Non-privileged State
    0=RTC is a privileged module (default); 1=RTC is a non-privileged module
  [22] TRNG — Set TRNG to Non-privileged State
    0=TRNG is a privileged module (default); 1=TRNG is a non-privileged module
  [21] TMR23 — Set TMR23 to Non-privileged State
    0=TMR23 is a privileged module (default); 1=TMR23 is a non-privileged module
  [20] KPI — Set KPI to Non-privileged State
    0=KPI is a privileged module (default); 1=KPI is a non-privileged module
  [19] OTG — Set OTG to Non-privileged State
    0=OTG is a privileged module (default); 1=OTG is a non-privileged module
  [18] SC1 — Set SC1 to Non-privileged State
    0=SC1 is a privileged module (default); 1=SC1 is a non-privileged module
  [17] UART9 — Set UART9 to Non-privileged State
    0=UART9 is a privileged module (default); 1=UART9 is a non-privileged module
  [16] UART7 — Set UART7 to Non-privileged State
    0=UART7 is a privileged module (default); 1=UART7 is a non-privileged module
  [15] UART5 — Set UART5 to Non-privileged State
    0=UART5 is a privileged module (default); 1=UART5 is a non-privileged module
  [14] UART3 — Set UART3 to Non-privileged State
    0=UART3 is a privileged module (default); 1=UART3 is a non-privileged module
  [13] UART1 — Set UART1 to Non-privileged State
    0=UART1 is a privileged module (default); 1=UART1 is a non-privileged module
  [12] SPI3 — Set SPI3 to Non-privileged State
    0=SPI3 is a privileged module (default); 1=SPI3 is a non-privileged module
  [11] SPI1 — Set SPI1 to Non-privileged State
    0=SPI1 is a privileged module (default); 1=SPI1 is a non-privileged module
  [10] QSPI1 — Set QSPI1 to Non-privileged State
    0=QSPI1 is a privileged module (default); 1=QSPI1 is a non-privileged module
  [9] I2C3 — Set I2C3 to Non-privileged State
    0=I2C3 is a privileged module (default); 1=I2C3 is a non-privileged module
  [8] I2C1 — Set I2C1 to Non-privileged State
    0=I2C1 is a privileged module (default); 1=I2C1 is a non-privileged module
  [7] ECAP3 — Set ECAP3 to Non-privileged State
    0=ECAP3 is a privileged module (default); 1=ECAP3 is a non-privileged module
  [6] ECAP1 — Set ECAP1 to Non-privileged State
    0=ECAP1 is a privileged module (default); 1=ECAP1 is a non-privileged module
  [5] EQEI3 — Set EQEI3 to Non-privileged State
    0=EQEI3 is a privileged module (default); 1=EQEI3 is a non-privileged module
  [4] EQEI1 — Set EQEI1 to Non-privileged State
    0=EQEI1 is a privileged module (default); 1=EQEI1 is a non-privileged module
  [3] BPWM1 — Set BPWM1 to Non-privileged State
    0=BPWM1 is a privileged module (default); 1=BPWM1 is a non-privileged module
  [2] EPWM1 — Set EPWM1 to Non-privileged State
    0=EPWM1 is a privileged module (default); 1=EPWM1 is a non-privileged module
  [0] WWDT1 — Set WWDT1 to Non-privileged State
    0=WWDT1 is a privileged module (default); 1=WWDT1 is a non-privileged module
0x2E0 SCU_D2PNP0 — Domain 2 Peripheral Privilege Attribution Set Register0 (0x4040_0000~0x4041_FFFF)
  [3] LPGPIO — Set LPGPIO to Non-privileged State
    0=LPGPIO is a privileged module (default); 1=LPGPIO is a non-privileged module
  [1] CCAP — Set CCAP to Non-privileged State
    0=CCAP is a privileged module (default); 1=CCAP is a non-privileged module
  [0] LPDMA — Set LPDMA to Non-privileged State
    0=LPDMA is a privileged module (default); 1=LPDMA is a non-privileged module
0x2E8 SCU_D2PNP2 — Domain 2 Peripheral Privilege Attribution Set Register2 (0x4044_0000~0x4045_FFFF)
  [16] LPSRAMMPC — Set LPSRAMMPC to Non-privileged State
    0=LPSRAMMPC is a privileged module (default); 1=LPSRAMMPC is a non-privileged module
  [9] AWF — Set AWF to Non-privileged State
    0=AWF is a privileged module (default); 1=AWF is a non-privileged module
  [8] WDT1 — Set WDT1 to Non-privileged State
    0=WDT1 is a privileged module (default); 1=WDT1 is a non-privileged module
  [7] WDT0 — Set WDT0 to Non-privileged State
    0=WDT0 is a privileged module (default); 1=WDT0 is a non-privileged module
  [6] LPUART0 — Set LPUART0 to Non-privileged State
    0=LPUART0 is a privileged module (default); 1=LPUART0 is a non-privileged module
  [5] DMIC0 — Set DMIC0 to Non-privileged State
    0=DMIC0 is a privileged module (default); 1=DMIC0 is a non-privileged module
  [4] LPSPI0 — Set LPSPI0 to Non-privileged State
    0=LPSPI0 is a privileged module (default); 1=LPSPI0 is a non-privileged module
  [3] LPI2C0 — Set LPI2C0 to Non-privileged State
    0=LPI2C0 is a privileged module (default); 1=LPI2C0 is a non-privileged module
  [2] LPADC0 — Set LPADC0 to Non-privileged State
    0=LPADC0 is a privileged module (default); 1=LPADC0 is a non-privileged module
  [1] TTMR01 — Set TTMR01 to Non-privileged State
    0=TTMR01 is a privileged module (default); 1=TTMR01 is a non-privileged module
  [0] LPTMR01 — Set LPTMR01 to Non-privileged State
    0=LPTMR01 is a privileged module (default); 1=LPTMR01 is a non-privileged module
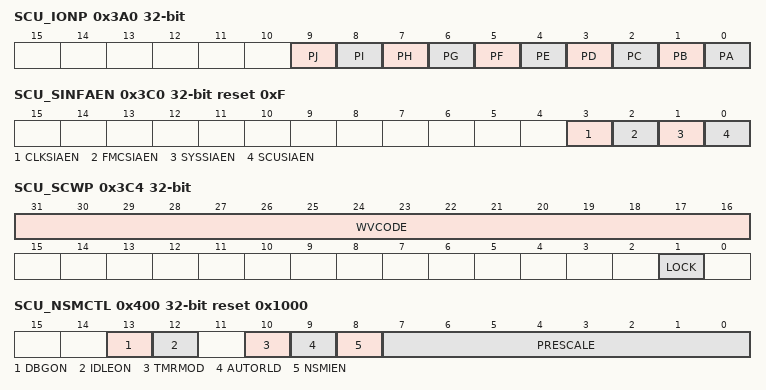
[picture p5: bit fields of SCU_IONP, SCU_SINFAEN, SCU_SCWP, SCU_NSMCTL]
0x3A0 SCU_IONP — I/O Non-privileged Attribution Set Register
  [9] PJ — Set GPIO Port J to Non-privileged State
    0=GPIO port J is privileged (default); 1=GPIO port J is non-privileged
  [8] PI — Set GPIO Port I to Non-privileged State
    0=GPIO port I is privileged (default); 1=GPIO port I is non-privileged
  [7] PH — Set GPIO Port H to Non-privileged State
    0=GPIO port H is privileged (default); 1=GPIO port H is non-privileged
  [6] PG — Set GPIO Port G to Non-privileged State
    0=GPIO port G is privileged (default); 1=GPIO port G is non-privileged
  [5] PF — Set GPIO Port F to Non-privileged State
    0=GPIO port F is privileged (default); 1=GPIO port F is non-privileged
  [4] PE — Set GPIO Port E to Non-privileged State
    0=GPIO port E is privileged (default); 1=GPIO port E is non-privileged
  [3] PD — Set GPIO Port D to Non-privileged State
    0=GPIO port D is privileged (default); 1=GPIO port D is non-privileged
  [2] PC — Set GPIO Port C to Non-privileged State
    0=GPIO port C is privileged (default); 1=GPIO port C is non-privileged
  [1] PB — Set GPIO Port B to Non-privileged State
    0=GPIO port B is privileged (default); 1=GPIO port B is non-privileged
  [0] PA — Set GPIO Port A to Non-privileged State
    0=GPIO port A is privileged (default); 1=GPIO port A is non-privileged
0x3C0 SCU_SINFAEN reset 0xF — Shared Information Access Enable Register
  [3] CLKSIAEN — CLKCTL Shared Information Access Enable Bit
    0=Non-secure CPU access CLKCTL Shared information Disabled; 1=Non-secure CPU access CLKCTL Shared information Enabled
  [2] FMCSIAEN — FMC Shared Information Access Enable Bit
    0=Non-secure CPU access FMC Shared information Disabled; 1=Non-secure CPU access FMC Shared information Enabled
  [1] SYSSIAEN — SYS Shared Information Access Enable Bit
    0=Non-secure CPU access SYS Shared information Disabled; 1=Non-secure CPU access SYS Shared information Enabled
  [0] SCUSIAEN — SCU Shared Information Access Enable Bit
    0=Non-secure CPU access SCU Shared information Disabled; 1=Non-secure CPU access SCU Shared information Enabled
0x3C4 SCU_SCWP — Security Configuration Write Protect Register
  [31:16] WVCODE — Write Verify Code. Read operation: Reserved, all zeros. Write operation:
    0x475A=The write verify code, 0x475A, is needed to do a valid write to SCU_SCWP
  [1] LOCK write-1-sets — Enable Write Protect Lock Bit (write 1 to set). Note: This bit cannot be cleared to 0 without a System-level reset after set to one.
    0=Write Protect lock Disabled; 1=Write Protect Enabled and locked
0x400 SCU_NSMCTL reset 0x1000 — Non-secure State Monitor Control Register
  [13] DBGON — Monitor Counter Keep Counting When the Chip Is in Debug Mode Enable Bit
    0=The counter will be halted when the core processor is halted by ICE. (default); 1=The counter will keep counting when the core processor is halted by ICE
  [12] IDLEON — Monitor Counter Keep Counting When the Chip Is in Idle Mode Enable Bit. Note: In monitor mode, the counter is always halted when the core processor is in secure state.
    0=The counter will be halted when the chip is in idle mode; 1=The counter will keep counting when the chip is in idle mode. (default)
  [10] TMRMOD — Non-secure Monitor Mode Enable Bit
    0=Monitor mode. The counter will count down when the core processor is in non-secure state. (default); 1=Free-counting mode. The counter will keep counting no matter the core processor is in secure or non-secure state
  [9] AUTORLD — Auto Reload Non-secure State Monitor Counter When CURRNS Changing to 1
    0=Disable clearing non-secure state monitor counter automatically (default); 1=Enable clearing non-secure state monitor counter automatically when the core processor changes from secure state to non-secure state
  [8] NSMIEN — Non-secure State Monitor Interrupt Enable Bit
    0=Non-secure state monitor interrupt Disabled; 1=Non-secure state monitor interrupt Enabled
  [7:0] PRESCALE — Pre-scale Value of Non-secure State Monitor Counter
    0=Counter Disabled
0x404 SCU_NSMLOAD reset 0xFFFFFF — Non-secure State Monitor Reload Value Register
  [23:0] RELOAD — Reload Value for Non-secure State Monitor Counter. The RELOAD value will be reloaded to the counter whenever the counter counts down to 0.
0x408 SCU_NSMVAL reset 0xFFFFFF — Non-secure State Monitor Counter Value Register
  [23:0] VALUE — Counter Value of Non-secure State Monitor Counter. A write of any value clears the VALUE to 0 and also clears NSMIF.
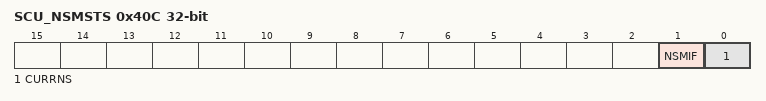
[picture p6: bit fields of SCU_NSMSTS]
0x40C SCU_NSMSTS — Non-secure State Monitor Status Register
  [1] NSMIF — Non-secure State Monitor Interrupt Flag. Note: This bit is cleared by writing 1.
    0=Counter does not count down to 0 since the last NSMIF has been cleared; 1=Counter counts down to 0
  [0] CURRNS ro — Current Core Processor Secure/Non-secure State (Read Only). Note: This bit can be used to monitor the current secure/non-secure state of the core processor, even if the non-secure state monitor counter is disabled.
    0=Core processor is in secure state; 1=Core processor is in non-secure state
{0x410+4i} SCU_SRAM{i}MPCLUT0 ro (i=0..2) — Security Attribute of memory blocks controlled by SRAM{i}MPC LUT0
  [31:0] BLKLUT — Block-based gating Look Up Table. Each bit indicates the Security state of a single block. When:
    0=The corresponding block is in the Secure state; 1=The corresponding block is in the Non-secure state
0x420 SCU_SRAM3MPCLUT0 ro — Security Attribute of memory blocks controlled by SRAM3MPC LUT0
  fields as SCU_SRAM0MPCLUT0
0x424 SCU_LPSRAMMPCLUT0 ro — Security Attribute of memory blocks controlled by LPSRAMMPC LUT0
  fields as SCU_SRAM0MPCLUT0
{0x430+4i} SCU_SPIM0MPCLUT{i} ro (i=0..7) — Security Attribute of memory blocks controlled by SPIM0MPC LUT{i}
  fields as SCU_SRAM0MPCLUT0
